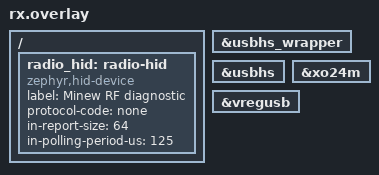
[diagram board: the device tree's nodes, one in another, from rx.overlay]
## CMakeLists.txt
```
cmake_minimum_required(VERSION 3.28.0)
find_package(Zephyr REQUIRED HINTS $ENV{ZEPHYR_BASE})
project(minew_radio_diagnostic)
if(NOT RADIO_ROLE MATCHES "^(tx|rx)$")
  message(FATAL_ERROR "RADIO_ROLE must be tx or rx")
endif()
target_compile_definitions(app PRIVATE RADIO_TX=$<STREQUAL:${RADIO_ROLE},tx>)
if(CONFIG_MINEW_RADIO_RELIABLE)
  target_sources(app PRIVATE src/reliable.c)
else()
  target_sources(app PRIVATE src/main.c)
endif()
if(CONFIG_MINEW_RADIO_CRYPTO_PROBE)
  target_sources(app PRIVATE src/crypto_probe.c)
endif()
if(CONFIG_MINEW_RADIO_DTLS_PROBE)
  target_sources(app PRIVATE src/dtls_probe.c)
endif()
if(CONFIG_MINEW_RADIO_SECURE)
  zephyr_include_directories(src)
  target_sources(app PRIVATE src/secure_dtls.c src/secure_pair.c)
endif()
if(RADIO_ROLE STREQUAL "rx")
  include(${ZEPHYR_BASE}/samples/subsys/usb/common/common.cmake)
  target_sources(app PRIVATE src/usb.c)
  if(CONFIG_MINEW_RADIO_KEYBOARD)
    target_sources(app PRIVATE src/keyboard_usb.c)
  endif()
endif()
```

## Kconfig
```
mainmenu "Minew 8 kHz radio diagnostic"
rsource "Kconfig.transport"
source "Kconfig.zephyr"
rsource "../upstream-zephyr/samples/subsys/usb/common/Kconfig.sample_usbd"
```

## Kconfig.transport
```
config MINEW_RADIO_RELIABLE
 bool "Experimental acknowledged radio transport"
 default n
 select ENTROPY_GENERATOR
 select REBOOT
 help
   Bounded diagnostic ARQ, sessions and channel reacquisition. Not encrypted.
config MINEW_RADIO_FREQUENCY_MHZ
 int "Fixed diagnostic radio frequency in MHz"
 range 2402 2480
 default 2408
 help
   Both transmitter and receiver must use the same frequency.
   This is a fixed-channel diagnostic, not adaptive channel hopping.
config MINEW_RADIO_CRYPTO_PROBE
 bool "Public-vector AEAD self-test and timing probe"
 depends on MINEW_RADIO_RELIABLE
 select PSA_CRYPTO
 select PSA_WANT_ALG_CCM
 select PSA_WANT_KEY_TYPE_AES
 select PSA_WANT_ALG_CHACHA20_POLY1305
 select PSA_WANT_KEY_TYPE_CHACHA20
 help
   Tests the pinned PSA provider before starting the existing unencrypted
   diagnostic. Uses a public test key, never a pairing secret. This option
   does not enable secure RF and must not be shipped as a secure transport.
config MINEW_RADIO_DTLS_PROBE
 bool "In-memory public-key DTLS conformance and timing probe"
 depends on MINEW_RADIO_CRYPTO_PROBE
 select MINEW_RADIO_DTLS
config MINEW_RADIO_DTLS
 bool
 select PSA_CRYPTO
 select PSA_WANT_ALG_CHACHA20_POLY1305
 select PSA_WANT_KEY_TYPE_CHACHA20
 select MBEDTLS_SSL_PROTO_TLS1_2
 select MBEDTLS_SSL_PROTO_DTLS
 select MBEDTLS_KEY_EXCHANGE_ECDHE_PSK_ENABLED
 select MBEDTLS_SSL_EXTENDED_MASTER_SECRET
 select PSA_WANT_ALG_TLS12_PRF
 select PSA_WANT_ALG_TLS12_PSK_TO_MS
 select PSA_WANT_ALG_SHA_256
 select PSA_WANT_ALG_ECDH
 select PSA_WANT_KEY_TYPE_DERIVE
 select PSA_WANT_KEY_TYPE_HMAC
 select PSA_WANT_KEY_TYPE_ECC_PUBLIC_KEY
 select PSA_WANT_KEY_TYPE_ECC_KEY_PAIR_IMPORT
 select PSA_WANT_KEY_TYPE_ECC_KEY_PAIR_EXPORT
 select PSA_WANT_KEY_TYPE_ECC_KEY_PAIR_GENERATE
 select PSA_WANT_ECC_SECP_R1_256
config MINEW_RADIO_SECURE
 bool "Experimental provisioned DTLS radio transport"
 depends on MINEW_RADIO_RELIABLE && !MINEW_RADIO_CRYPTO_PROBE
 select MINEW_RADIO_DTLS
 select FLASH
 select FLASH_MAP
 select FLASH_PAGE_LAYOUT
 select SETTINGS
 select ZMS
 help
   Requires a per-pair secret provisioned locally. No fixed test key or
   plaintext RF fallback. Uses the same ZMS format as the existing ZMK
   settings; never enable forced mount or replace it with NVS.
config MINEW_RADIO_KEYBOARD
 bool "Authenticated ZMK report transport"
 depends on MINEW_RADIO_SECURE
 help
   Separate ARQv5 address/format. Carries the pinned ZMK HKRO6 and full
   six-usage consumer reports. Diagnostic patterns cannot generate keys.
config MINEW_ZMK_RADIO_TX
 bool "Use real ZMK report producer"
 depends on MINEW_RADIO_KEYBOARD
```

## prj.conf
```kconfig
CONFIG_BT=n
CONFIG_NRFX_GPPI=y
CONFIG_SERIAL=n
CONFIG_CONSOLE=y
CONFIG_UART_CONSOLE=n
CONFIG_USE_SEGGER_RTT=y
CONFIG_RTT_CONSOLE=y
CONFIG_PRINTK=y
CONFIG_MAIN_STACK_SIZE=2048
CONFIG_ASSERT=y
```

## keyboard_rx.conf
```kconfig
CONFIG_SAMPLE_USBD_PRODUCT="Minew ZMK RF Receiver"
CONFIG_SAMPLE_USBD_PID=0x000a
```

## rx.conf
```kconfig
CONFIG_USB_DEVICE_STACK_NEXT=y
CONFIG_USBD_HID_IN_BUF_COUNT=4
CONFIG_SAMPLE_USBD_PRODUCT="Minew RF8K Diagnostic"
CONFIG_SAMPLE_USBD_MANUFACTURER="Experimental Minew port"
CONFIG_SAMPLE_USBD_PID=0x0009
```

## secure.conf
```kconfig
# No test PSK or plaintext fallback. Keep the existing ZMK ZMS format.
CONFIG_MBEDTLS_ENABLE_HEAP=y
CONFIG_MBEDTLS_HEAP_SIZE=49152
CONFIG_MAIN_STACK_SIZE=8192
CONFIG_SPEED_OPTIMIZATIONS=y
CONFIG_COMPILER_OPT="-O3"
CONFIG_MBEDTLS_SSL_IN_CONTENT_LEN=512
CONFIG_MBEDTLS_SSL_OUT_CONTENT_LEN=255
CONFIG_SETTINGS_ZMS=y
CONFIG_SETTINGS_ZMS_FORCE_MOUNT=n
CONFIG_ZMS_DATA_CRC=n
CONFIG_SETTINGS_ZMS_SECTOR_SIZE_MULT=1
CONFIG_SETTINGS_ZMS_CUSTOM_SECTOR_COUNT=n
```

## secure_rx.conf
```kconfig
# Required to handle a newly booted client using the same physical RF address.
CONFIG_MBEDTLS_USER_CONFIG_FILE="minew_secure_mbedtls.h"
```

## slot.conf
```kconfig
CONFIG_BOOTLOADER_MCUBOOT=y
CONFIG_ROM_START_OFFSET=0x800
CONFIG_MCUBOOT_BOOTUTIL_LIB=y
CONFIG_FLASH=y
CONFIG_FLASH_MAP=y
CONFIG_MCUBOOT_BOOTLOADER_MODE_SWAP_SCRATCH=y
CONFIG_IMG_MANAGER=y
CONFIG_STREAM_FLASH=y
CONFIG_RETAINED_MEM=y
CONFIG_REBOOT=y
```

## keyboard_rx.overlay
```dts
/ {
 keyboard_hid: keyboard-hid {
  compatible = "zephyr,hid-device";
  label = "Minew encrypted ZMK keyboard";
  protocol-code = "none";
  in-report-size = <64>;
  in-polling-period-us = <125>;
 };
};
```

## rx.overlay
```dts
&usbhs_wrapper { status = "okay"; };
zephyr_udc0: &usbhs { status = "okay"; };
&xo24m { status = "okay"; };
&vregusb { status = "okay"; };
/ {
 radio_hid: radio-hid {
  compatible = "zephyr,hid-device";
  label = "Minew RF diagnostic";
  protocol-code = "none";
  in-report-size = <64>;
  in-polling-period-us = <125>;
 };
};
```

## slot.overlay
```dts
#include "../bootloader/integration/layout.dtsi"
/ { chosen { zephyr,code-partition = &slot0_partition; }; };
&gpregret1 { status = "okay"; };
```

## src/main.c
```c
/* SPDX-License-Identifier: MIT */
#include <zephyr/kernel.h>
#include <zephyr/irq.h>
#include <zephyr/drivers/clock_control/nrf_clock_control.h>
#include <hal/nrf_radio.h>
#include <hal/nrf_timer.h>
#include <helpers/nrfx_gppi.h>
#include <string.h>
#include "frame.h"
#if IS_ENABLED(CONFIG_BOOTLOADER_MCUBOOT)
#include <zephyr/dfu/mcuboot.h>
#include <zephyr/drivers/retained_mem.h>
#include <zephyr/sys/reboot.h>
volatile uint32_t radio_recovery_request;
#endif

#define RADIO ((NRF_RADIO_Type *)DT_REG_ADDR(DT_NODELABEL(radio)))
#define TIMER ((NRF_TIMER_Type *)DT_REG_ADDR(DT_NODELABEL(timer21)))
/* S0/LENGTH absent: exactly 32 bytes on air, plus preamble/address/CRC. */
static uint8_t packet[FRAME_SIZE] __aligned(4);
volatile uint32_t radio_completed, radio_fresh, radio_missing, radio_duplicate;
volatile uint32_t radio_bad_crc, radio_bad_frame, radio_late, radio_heartbeat;
volatile uint32_t radio_last_sequence, radio_started;
volatile uint64_t radio_first_cycle, radio_last_cycle;

#if !RADIO_TX
static bool have_sequence;
#endif
#if RADIO_TX
static nrfx_gppi_handle_t pacing;
#endif
#if !RADIO_TX
int radio_usb_init(void);
void radio_usb_enqueue(const uint8_t *frame);
extern volatile uint32_t radio_usb_submitted, radio_usb_completed, radio_usb_dropped, radio_usb_errors;
#endif

static void radio_isr(const void *unused)
{
 ARG_UNUSED(unused);
 if (!nrf_radio_event_check(RADIO, NRF_RADIO_EVENT_END)) return;
 nrf_radio_event_clear(RADIO, NRF_RADIO_EVENT_END);
 radio_completed++;
 uint64_t now = k_cycle_get_64();
 if (radio_completed == 1) radio_first_cycle = now;
 radio_last_cycle = now;
#if RADIO_TX
 /* END leaves TXIDLE. Hardware START is periodic; skip mutation near the
  * next boundary rather than race EasyDMA. Repeat is counted by receiver. */
 unsigned int key = irq_lock();
 nrf_timer_task_trigger(TIMER, NRF_TIMER_TASK_CAPTURE1);
 uint32_t phase = nrf_timer_cc_get(TIMER, 1);
 if (phase < 2000 - 320 && nrf_radio_state_get(RADIO) == NRF_RADIO_STATE_TXIDLE) {
  frame_make(packet, ++radio_last_sequence);
 } else { radio_late++; }
 __DMB();
 irq_unlock(key);
#else
 if (!nrf_radio_crc_status_check(RADIO)) { radio_bad_crc++; return; }
 /* Snapshot promptly: continuous RX reuses EasyDMA storage for the next
  * frame. Validate and queue the snapshot, not a changing DMA buffer. */
 uint8_t received[FRAME_SIZE];
 memcpy(received, packet, sizeof(received));
 if (!frame_valid(received, sizeof(received))) { radio_bad_frame++; return; }
 uint32_t seq = frame_get32(received + 4);
 uint32_t delta = frame_forward_delta(radio_last_sequence, seq);
 if (!have_sequence || delta) {
  if (have_sequence) radio_missing += delta - 1;
  have_sequence = true; radio_last_sequence = seq; radio_fresh++;
  radio_usb_enqueue(received);
 } else { radio_duplicate++; }
#endif
}

int main(void)
{
#if !RADIO_TX
 int usb_err = radio_usb_init();
 if (usb_err) { printk("USB init error %d\n", usb_err); return usb_err; }
#endif
 int err = nrf_clock_control_request_sync(DEVICE_DT_GET(DT_NODELABEL(xo)), NULL, K_SECONDS(1));
 if (err) { printk("HFXO error %d\n", err); return err; }
 nrf_radio_mode_set(RADIO, NRF_RADIO_MODE_NRF_4MBIT_BT_0_6);
 nrf_radio_frequency_set(RADIO, CONFIG_MINEW_RADIO_FREQUENCY_MHZ);
 nrf_radio_txpower_set(RADIO, NRF_RADIO_TXPOWER_0DBM);
 nrf_radio_packet_conf_t cfg = {
  .lflen = 0, .s0len = 0, .s1len = 0,
  .plen = NRF_RADIO_PREAMBLE_LENGTH_16BIT,
  .maxlen = FRAME_SIZE, .statlen = FRAME_SIZE, .balen = 4,
  .big_endian = false, .whiteen = false,
 };
 nrf_radio_packet_configure(RADIO, &cfg);
 nrf_radio_base0_set(RADIO, 0x8e89bed6);
 nrf_radio_prefix0_set(RADIO, 0x73);
 nrf_radio_txaddress_set(RADIO, 0);
 nrf_radio_rxaddresses_set(RADIO, 1);
 nrf_radio_crc_configure(RADIO, 3, NRF_RADIO_CRC_ADDR_INCLUDE, 0x00065b);
 nrf_radio_crcinit_set(RADIO, 0x555555);
 nrf_radio_packetptr_set(RADIO, packet);
 IRQ_CONNECT(DT_IRQN(DT_NODELABEL(radio)), 2, radio_isr, NULL, 0);
 nrf_radio_event_clear(RADIO, NRF_RADIO_EVENT_END);
 nrf_radio_int_enable(RADIO, NRF_RADIO_INT_END_MASK);
 irq_enable(DT_IRQN(DT_NODELABEL(radio)));
#if RADIO_TX
 frame_make(packet, 0);
 nrf_timer_mode_set(TIMER, NRF_TIMER_MODE_TIMER);
 nrf_timer_bit_width_set(TIMER, NRF_TIMER_BIT_WIDTH_32);
 nrf_timer_prescaler_set(TIMER, NRF_TIMER_PRESCALER_CALCULATE(NRF_TIMER_BASE_FREQUENCY_GET(TIMER), 16000000));
 nrf_timer_cc_set(TIMER, 0, 2000); /* 125 us at 16 MHz */
 nrf_timer_shorts_enable(TIMER, NRF_TIMER_SHORT_COMPARE0_CLEAR_MASK);
 err = nrfx_gppi_conn_alloc(nrf_timer_event_address_get(TIMER, NRF_TIMER_EVENT_COMPARE0),
                           nrf_radio_task_address_get(RADIO, NRF_RADIO_TASK_START), &pacing);
 if (err) { printk("GPPI error %d\n", err); return err; }
 nrf_radio_task_trigger(RADIO, NRF_RADIO_TASK_TXEN);
 int64_t deadline = k_uptime_get() + 100;
 while (!nrf_radio_event_check(RADIO, NRF_RADIO_EVENT_READY)) {
  if (k_uptime_get() > deadline) { printk("RADIO ready timeout\n"); return -ETIMEDOUT; }
  k_busy_wait(1);
 }
 nrfx_gppi_conn_enable(pacing);
 nrf_timer_task_trigger(TIMER, NRF_TIMER_TASK_CLEAR);
 nrf_timer_task_trigger(TIMER, NRF_TIMER_TASK_START);
#else
 nrf_radio_shorts_set(RADIO, NRF_RADIO_SHORT_READY_START_MASK | NRF_RADIO_SHORT_END_START_MASK);
 nrf_radio_task_trigger(RADIO, NRF_RADIO_TASK_RXEN);
#endif
 radio_started = 1;
 printk("MINEW 4 Mbps %s diagnostic at %u MHz; 125 us target, no BLE/keys/authentication\n",
        RADIO_TX ? "TX" : "RX", CONFIG_MINEW_RADIO_FREQUENCY_MHZ);
 for (;;) {
  k_sleep(K_SECONDS(1)); radio_heartbeat++;
#if IS_ENABLED(CONFIG_BOOTLOADER_MCUBOOT)
  /* Bring-up health gate, deliberately independent of a second board. */
  if (radio_heartbeat == 5 && (!RADIO_TX || radio_completed)) {
   int confirm = boot_write_img_confirmed();
   printk("Diagnostic boot confirmation: %d\n", confirm);
  }
  if (radio_recovery_request == 3) {
   const struct device *retained = DEVICE_DT_GET(DT_NODELABEL(gpregret1));
   uint8_t request = 0xb1;
   if (device_is_ready(retained) && !retained_mem_write(retained, 0, &request, 1)) sys_reboot(SYS_REBOOT_COLD);
   radio_recovery_request = 0;
  }
#endif
  printk("end=%u fresh=%u missing=%u dup=%u crc=%u bad=%u late=%u\n",
   radio_completed, radio_fresh, radio_missing, radio_duplicate,
   radio_bad_crc, radio_bad_frame, radio_late);
#if !RADIO_TX
  printk("USB frames submitted=%u completed=%u dropped=%u errors=%u\n",
   radio_usb_submitted, radio_usb_completed, radio_usb_dropped, radio_usb_errors);
#endif
 }
}
```

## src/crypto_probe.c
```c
/* SPDX-License-Identifier: MIT */
/* PUBLIC TEST KEYS ONLY. This measures PSA; RF remains the unencrypted ARQv2. */
#include <zephyr/kernel.h>
#include <psa/crypto.h>
#include <string.h>
#include <errno.h>

/* magic, ABI, status(1 running/2 passed/3 failed), stage, PSA error, iterations,
 * then two groups of six: encrypt176 ns, decrypt176 ns, encrypt20 ns,
 * decrypt20 ns, tamper mask, known-answer passed (AES-CCM, then ChaChaPoly).
 * reserved[6]. Resolve from the exact flashed ELF. */
volatile uint32_t radio_crypto_probe_results[24];
static const uint8_t aad[] = "Minew secure RF v1";
static const uint8_t expected[] =
 "\x16\x35\xb6\x8b\x57\x0c\xfc\x85\x52\x9e\x39\xac\x91\x39\x10\xd7\xf3\x11\x16\x31\x62\x38\x67\xf1\x34\xe6\xe4\x41\x90\x4f\xd5\x04"
 "\xf5\x74\x6d\x6b\xf1\x89\x81\x5f\x51\xa4\x8f\x07\xc9\x94\xed\x9e\xee\x24\xe8\xd2\xea\xda\x7e\x42\x18\xb5\x88\xf6\x7a\x3a\xf1\xa3"
 "\x8d\xfe\xed\x70\xab\x5a\x15\x36\x28\x34\x0b\xa1\xf9\xf1\xee\x95\xc3\x2e\xa4\xf7\xa7\x98\x2f\x12\xee\xcc\x80\xb0\x3f\x0f\x2b\x66"
 "\x20\xcf\xa6\xc9\x47\x03\x89\xaf\xee\x56\xa5\x2b\x2f\x39\xc0\xc9\x48\xf5\x9c\x3d\xb0\x2e\x68\xdc\x18\x15\x52\x24\x0c\x47\x71\x42"
 "\x25\xf5\x67\x07\xfa\x4a\x96\xe2\x3e\x89\x70\xc9\x96\x1f\xdb\x4c\xe4\x73\x1e\xe7\xb0\xd2\x96\x98\xb7\x2d\xd1\x20\x15\x2d\x52\xfc"
 "\x18\x4d\x46\x02\x3c\x6d\x20\xfb\x6b\x6a\x44\xff\xf9\x78\xd7\x45\x52\xf8\x87\xb7\xee\xd5\x11\xcf\xdb\xaf\xfb\x8e\xcf\x72\xc3\xd5";
static const uint8_t chacha_expected[] =
 "\x89\xfa\x0a\x03\x2d\x12\xa3\x47\xbf\x8a\x35\xf8\x94\x10\x00\x6c\xd9\x61\xa0\xf4\x45\x61\xbb\xae\xfe\x8e\x35\xde\x69\xdd\xb8\x23"
 "\xcc\xa1\x0e\xd0\xc2\x3b\x97\xbf\x1f\x1b\x5c\xf3\x49\xb9\xa1\x0c\x4e\xb5\x9b\x47\xc9\x1d\x8e\xac\x2a\x81\xe3\x3c\xac\x72\xa0\xe9"
 "\x39\x39\xfe\x8e\xa1\x51\x6a\xae\x8c\x5f\x07\xf7\x54\x31\x92\xbe\x8a\x8f\x15\x61\x3b\x3f\xa6\x69\x56\x0e\xaa\x55\x84\x20\x5c\xe0"
 "\x2d\xbf\x0e\x90\x93\xbc\x41\x93\xd9\x32\x99\xdc\xce\xfc\xd9\xef\x99\x1e\x24\x4b\xfd\x28\x36\x8f\x37\x14\x4e\xa4\x05\x42\xc1\x39"
 "\x21\xe7\x41\x3e\x2d\xb6\x59\xeb\xc1\x9a\xf5\xf1\xa0\xb1\xe5\xb5\x24\xe0\x15\xe1\x9f\xfa\x5a\xc9\xaa\x78\x3d\xaa\x38\x86\x3e\xa6"
 "\x9f\x18\x23\x4b\x19\xe1\x32\x41\x26\xd7\xcc\xbb\xcb\x1c\x41\xaf\x19\x90\x1f\xc4\x06\x0b\xb4\xc7\xc2\xbc\x0a\xcf\x7b\x1c\x46\x38";
static psa_algorithm_t algorithm;
static size_t nonce_length;
static uint8_t key_bytes[32], nonce[13], plain[176], cipher[192], decoded[176];
static mbedtls_svc_key_id_t key;
#define CHECK(call) do { psa_status_t rc = (call); if (rc != PSA_SUCCESS) { radio_crypto_probe_results[4] = (uint32_t)rc; goto fail; } } while (0)

static psa_status_t seal(size_t n)
{
 size_t used;
 psa_status_t rc = psa_aead_encrypt(key, algorithm, nonce, nonce_length,
   aad, sizeof(aad)-1, plain, n, cipher, sizeof(cipher), &used);
 return rc ? rc : used == n + 16 ? PSA_SUCCESS : PSA_ERROR_CORRUPTION_DETECTED;
}
static psa_status_t open_packet(mbedtls_svc_key_id_t k, size_t n, const uint8_t *a)
{
 size_t used;
 psa_status_t rc = psa_aead_decrypt(k, algorithm, nonce, nonce_length,
   a, sizeof(aad)-1, cipher, n+16, decoded, sizeof(decoded), &used);
 return rc ? rc : used == n ? PSA_SUCCESS : PSA_ERROR_CORRUPTION_DETECTED;
}
static psa_status_t measure(bool encrypting, size_t n, unsigned result)
{
 nonce[0] = (uint8_t)n;
 CHECK(seal(n));
 uint64_t start = k_cycle_get_64();
 for (unsigned i = 0; i < 1000; i++) {
  if (encrypting) {
   for (unsigned j = 0; j < 8; j++) nonce[nonce_length-8+j] = ((uint64_t)i + 1) >> (8*j);
   CHECK(seal(n));
  } else CHECK(open_packet(key, n, aad));
 }
 radio_crypto_probe_results[result] = k_cyc_to_ns_floor64(k_cycle_get_64()-start) / 1000;
 return PSA_SUCCESS;
fail:
 return (psa_status_t)radio_crypto_probe_results[4];
}
static int probe_cipher(bool chacha, unsigned base)
{
 algorithm = chacha ? PSA_ALG_CHACHA20_POLY1305 : PSA_ALG_CCM;
 nonce_length = chacha ? 12 : 13;
 size_t key_length = chacha ? 32 : 16;
 mbedtls_svc_key_id_t wrong_key = 0;
 psa_key_attributes_t attributes = PSA_KEY_ATTRIBUTES_INIT;
 radio_crypto_probe_results[3] = chacha ? 7 : 1;
 for (unsigned i = 0; i < sizeof(key_bytes); i++) key_bytes[i] = i;
 for (unsigned i = 0; i < sizeof(nonce); i++) nonce[i] = i;
 for (unsigned i = 0; i < sizeof(plain); i++) plain[i] = i;
 CHECK(psa_crypto_init());
 radio_crypto_probe_results[3] = 2;
 psa_set_key_type(&attributes, chacha ? PSA_KEY_TYPE_CHACHA20 : PSA_KEY_TYPE_AES); psa_set_key_bits(&attributes, key_length * 8);
 psa_set_key_usage_flags(&attributes, PSA_KEY_USAGE_ENCRYPT | PSA_KEY_USAGE_DECRYPT);
 psa_set_key_algorithm(&attributes, algorithm);
 CHECK(psa_import_key(&attributes, key_bytes, key_length, &key));
 key_bytes[0] ^= 1;
 CHECK(psa_import_key(&attributes, key_bytes, key_length, &wrong_key));
 psa_reset_key_attributes(&attributes);
 radio_crypto_probe_results[3] = 3;
 CHECK(seal(sizeof(plain)));
 if (memcmp(chacha ? chacha_expected : expected, cipher, sizeof(cipher))) goto fail;
 CHECK(open_packet(key, sizeof(plain), aad));
 if (memcmp(plain, decoded, sizeof(plain))) goto fail;
 radio_crypto_probe_results[base+5] = 1;
 radio_crypto_probe_results[3] = 4;
 cipher[0] ^= 1;
 if (open_packet(key, sizeof(plain), aad) != PSA_ERROR_INVALID_SIGNATURE) goto fail;
 cipher[0] ^= 1; radio_crypto_probe_results[base+4] |= 1;
 cipher[sizeof(cipher)-1] ^= 1;
 if (open_packet(key, sizeof(plain), aad) != PSA_ERROR_INVALID_SIGNATURE) goto fail;
 cipher[sizeof(cipher)-1] ^= 1; radio_crypto_probe_results[base+4] |= 2;
 uint8_t wrong_aad[sizeof(aad)]; memcpy(wrong_aad, aad, sizeof(aad)); wrong_aad[0] ^= 1;
 if (open_packet(key, sizeof(plain), wrong_aad) != PSA_ERROR_INVALID_SIGNATURE) goto fail;
 radio_crypto_probe_results[base+4] |= 4; nonce[0] ^= 1;
 if (open_packet(key, sizeof(plain), aad) != PSA_ERROR_INVALID_SIGNATURE) goto fail;
 nonce[0] ^= 1; radio_crypto_probe_results[base+4] |= 8;
 if (open_packet(wrong_key, sizeof(plain), aad) != PSA_ERROR_INVALID_SIGNATURE) goto fail;
 radio_crypto_probe_results[base+4] |= 16;
 radio_crypto_probe_results[3] = 5; radio_crypto_probe_results[5] = 1000;
 CHECK(measure(true, 176, base)); CHECK(measure(false, 176, base+1));
 CHECK(measure(true, 20, base+2)); CHECK(measure(false, 20, base+3));
 CHECK(psa_destroy_key(wrong_key)); wrong_key = 0;
 CHECK(psa_destroy_key(key)); key = 0;
 return 0;
fail:
 if (wrong_key) psa_destroy_key(wrong_key);
 if (key) psa_destroy_key(key);
 psa_reset_key_attributes(&attributes);
 radio_crypto_probe_results[2] = 3;
 return -EIO;
}


int radio_crypto_probe(void)
{
 memset((void *)radio_crypto_probe_results, 0, sizeof(radio_crypto_probe_results));
 radio_crypto_probe_results[0] = 0x50433853; radio_crypto_probe_results[1] = 2;
 radio_crypto_probe_results[2] = 1;
 if (probe_cipher(false, 6) || probe_cipher(true, 12)) return -EIO;
 radio_crypto_probe_results[3] = 8; radio_crypto_probe_results[2] = 2;
 printk("PUBLIC-vector PSA AEAD probes passed; following RF is still UNENCRYPTED\n");
 return 0;
}
```

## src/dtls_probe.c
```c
/* SPDX-License-Identifier: MIT */
/* Two in-memory DTLS peers with PUBLIC TEST PSKs. No encrypted RF claim. */
#include <zephyr/kernel.h>
#include <mbedtls/ssl.h>
#include <mbedtls/ssl_cookie.h>
#include <mbedtls/ssl_ciphersuites.h>
#include <string.h>
#include <errno.h>

#define MTU 224
#define DEPTH 8
struct packet { size_t length; uint8_t bytes[MTU]; };
struct endpoint {
 mbedtls_ssl_context ssl;
 mbedtls_ssl_config conf;
 mbedtls_ssl_cookie_ctx cookie;
 struct endpoint *other;
 struct packet queue[DEPTH], last_application;
 unsigned head, count;
 int64_t timer_start;
 uint32_t intermediate, final;
};
static struct endpoint client, server;
static const int suites[] = {MBEDTLS_TLS_ECDHE_PSK_WITH_CHACHA20_POLY1305_SHA256, 0};
static const uint16_t groups[] = {MBEDTLS_SSL_IANA_TLS_GROUP_SECP256R1, 0};
static const uint8_t identity[] = "PUBLIC-Minew-DTLS-probe";
/* magic, ABI, status, stage, error, handshake ms, pair176 ns, pair20 ns,
 * suite, max datagram, cookie requests, wrong-key/replay/tamper/old-session/
 * reflection/truncation rejected, new-session ciphertext differs,
 * post-fault valid, iterations, sent, received, reserved[2]. */
volatile uint32_t radio_dtls_probe_results[24];

static int enqueue(struct endpoint *e, const uint8_t *p, size_t n)
{
 if (n > MTU) return MBEDTLS_ERR_SSL_BUFFER_TOO_SMALL;
 if (e->count == DEPTH) return MBEDTLS_ERR_SSL_WANT_WRITE;
 struct packet *q = &e->queue[(e->head + e->count++) % DEPTH];
 q->length = n; memcpy(q->bytes, p, n); return (int)n;
}
static int send_packet(void *context, const uint8_t *p, size_t n)
{
 struct endpoint *e = context;
 if (n > radio_dtls_probe_results[9]) radio_dtls_probe_results[9] = n;
 int rc = enqueue(e->other, p, n);
 if (rc >= 0) {
  radio_dtls_probe_results[20]++;
  if (n && p[0] == 23) { e->last_application.length = n; memcpy(e->last_application.bytes, p, n); }
 }
 return rc;
}
static int receive_packet(void *context, uint8_t *p, size_t n)
{
 struct endpoint *e = context;
 if (!e->count) return MBEDTLS_ERR_SSL_WANT_READ;
 struct packet *q = &e->queue[e->head];
 if (q->length > n) return MBEDTLS_ERR_SSL_BUFFER_TOO_SMALL;
 memcpy(p, q->bytes, q->length); int used = q->length;
 e->head = (e->head + 1) % DEPTH; e->count--;
 radio_dtls_probe_results[21]++; return used;
}
static void set_timer(void *context, uint32_t intermediate, uint32_t final)
{
 struct endpoint *e = context;
 e->timer_start = k_uptime_get(); e->intermediate = intermediate; e->final = final;
}
static int get_timer(void *context)
{
 struct endpoint *e = context;
 if (!e->final) return -1;
 int64_t elapsed = k_uptime_get() - e->timer_start;
 return elapsed >= e->final ? 2 : elapsed >= e->intermediate ? 1 : 0;
}
static void free_peers(void)
{
 struct endpoint *ends[] = {&client, &server};
 for (unsigned i = 0; i < 2; i++) {
  mbedtls_ssl_free(&ends[i]->ssl); mbedtls_ssl_config_free(&ends[i]->conf);
  mbedtls_ssl_cookie_free(&ends[i]->cookie);
 }
}
static int setup_peer(struct endpoint *e, bool is_server, bool wrong_key)
{
 uint8_t key[32]; for (unsigned i = 0; i < sizeof(key); i++) key[i] = i;
 if (wrong_key) key[0] ^= 1;
 int rc = mbedtls_ssl_config_defaults(&e->conf,
    is_server ? MBEDTLS_SSL_IS_SERVER : MBEDTLS_SSL_IS_CLIENT,
    MBEDTLS_SSL_TRANSPORT_DATAGRAM, MBEDTLS_SSL_PRESET_DEFAULT);
 if (rc) return rc;
 mbedtls_ssl_conf_ciphersuites(&e->conf, suites);
 mbedtls_ssl_conf_groups(&e->conf, groups);
 mbedtls_ssl_conf_min_tls_version(&e->conf, MBEDTLS_SSL_VERSION_TLS1_2);
 mbedtls_ssl_conf_max_tls_version(&e->conf, MBEDTLS_SSL_VERSION_TLS1_2);
 mbedtls_ssl_conf_handshake_timeout(&e->conf, 100, 1000);
 mbedtls_ssl_conf_dtls_anti_replay(&e->conf, MBEDTLS_SSL_ANTI_REPLAY_ENABLED);
 rc = mbedtls_ssl_conf_psk(&e->conf, key, sizeof(key), identity, sizeof(identity)-1);
 memset(key, 0, sizeof(key)); if (rc) return rc;
 if (is_server) {
  rc = mbedtls_ssl_cookie_setup(&e->cookie); if (rc) return rc;
  mbedtls_ssl_conf_dtls_cookies(&e->conf, mbedtls_ssl_cookie_write,
                               mbedtls_ssl_cookie_check, &e->cookie);
 }
 rc = mbedtls_ssl_setup(&e->ssl, &e->conf); if (rc) return rc;
 mbedtls_ssl_set_bio(&e->ssl, e, send_packet, receive_packet, NULL);
 mbedtls_ssl_set_timer_cb(&e->ssl, e, set_timer, get_timer);
 mbedtls_ssl_set_mtu(&e->ssl, MTU);
 if (is_server) return mbedtls_ssl_set_client_transport_id(&e->ssl, identity, sizeof(identity)-1);
 return 0;
}
static int start_peers(bool wrong_key)
{
 memset(&client, 0, sizeof(client)); memset(&server, 0, sizeof(server));
 struct endpoint *ends[] = {&client, &server};
 for (unsigned i = 0; i < 2; i++) {
  mbedtls_ssl_init(&ends[i]->ssl); mbedtls_ssl_config_init(&ends[i]->conf);
  mbedtls_ssl_cookie_init(&ends[i]->cookie);
 }
 client.other = &server; server.other = &client;
 int rc = setup_peer(&client, false, false); if (rc) return rc;
 return setup_peer(&server, true, wrong_key);
}
static int handshake(void)
{
 int64_t end = k_uptime_get() + 5000;
 while (k_uptime_get() < end) {
  struct endpoint *ends[] = {&client, &server};
  for (unsigned i = 0; i < 2; i++) {
   struct endpoint *e = ends[i];
   if (mbedtls_ssl_is_handshake_over(&e->ssl)) continue;
   int rc = mbedtls_ssl_handshake(&e->ssl);
   if (rc == MBEDTLS_ERR_SSL_HELLO_VERIFY_REQUIRED && i == 1) {
    radio_dtls_probe_results[10]++;
    rc = mbedtls_ssl_session_reset(&e->ssl); if (rc) return rc;
    mbedtls_ssl_set_mtu(&e->ssl, MTU);
    rc = mbedtls_ssl_set_client_transport_id(&e->ssl, identity, sizeof(identity)-1);
   }
   if (rc && rc != MBEDTLS_ERR_SSL_WANT_READ && rc != MBEDTLS_ERR_SSL_WANT_WRITE) return rc;
  }
  if (mbedtls_ssl_is_handshake_over(&client.ssl) && mbedtls_ssl_is_handshake_over(&server.ssl)) return 0;
  k_sleep(K_MSEC(1));
 }
 return MBEDTLS_ERR_SSL_TIMEOUT;
}
static int roundtrip(size_t length)
{
 uint8_t plain[176], out[176]; for (unsigned i = 0; i < sizeof(plain); i++) plain[i] = i;
 int rc = mbedtls_ssl_write(&client.ssl, plain, length);
 if (rc != (int)length) return rc < 0 ? rc : -EIO;
 rc = mbedtls_ssl_read(&server.ssl, out, sizeof(out));
 return rc == (int)length && !memcmp(plain, out, length) ? 0 : rc < 0 ? rc : -EIO;
}
static int reject(struct endpoint *e, const struct packet *p)
{
 uint8_t out[176];
 int rc = enqueue(e, p->bytes, p->length); if (rc < 0) return rc;
 rc = mbedtls_ssl_read(&e->ssl, out, sizeof(out));
 return rc == MBEDTLS_ERR_SSL_WANT_READ ? 0 : rc < 0 ? rc : -EIO;
}
int radio_dtls_probe(void)
{
 int rc = 0;
#define TRY(call) do { rc = (call); if (rc) goto done; } while (0)
 memset((void *)radio_dtls_probe_results, 0, sizeof(radio_dtls_probe_results));
 radio_dtls_probe_results[0] = 0x50433844; radio_dtls_probe_results[1] = 1;
 radio_dtls_probe_results[2] = 1; radio_dtls_probe_results[3] = 1;
 TRY(start_peers(false));
 int64_t start = k_uptime_get(); TRY(handshake());
 radio_dtls_probe_results[5] = k_uptime_get() - start;
 radio_dtls_probe_results[8] = MBEDTLS_TLS_ECDHE_PSK_WITH_CHACHA20_POLY1305_SHA256;
 radio_dtls_probe_results[3] = 2;
 TRY(roundtrip(176)); struct packet old = client.last_application;
 TRY(reject(&server, &old)); radio_dtls_probe_results[12] = 1;
 struct packet tampered = old; tampered.bytes[tampered.length-1] ^= 1;
 /* A new, not-yet-seen sequence reaches AEAD verification rather than only
  * the replay filter. Corrupt the next record before the receiver reads it. */
 uint8_t input[176] = {0};
 rc = mbedtls_ssl_write(&client.ssl, input, sizeof(input));
 if (rc != 176) { if (rc >= 0) rc = -EIO; goto done; }
 tampered = client.last_application; tampered.bytes[tampered.length-1] ^= 1;
 server.count = 0;
 TRY(reject(&server, &tampered)); radio_dtls_probe_results[13] = 1;
 TRY(reject(&client, &client.last_application)); radio_dtls_probe_results[15] = 1;
 tampered.length = 7; TRY(reject(&server, &tampered)); radio_dtls_probe_results[16] = 1;
 TRY(roundtrip(176)); radio_dtls_probe_results[18] = 1;
 radio_dtls_probe_results[3] = 3; radio_dtls_probe_results[19] = 1000;
 for (unsigned j = 0; j < 2; j++) {
  uint64_t cycles = k_cycle_get_64();
  for (unsigned i = 0; i < 1000; i++) TRY(roundtrip(j ? 20 : 176));
  radio_dtls_probe_results[6+j] = k_cyc_to_ns_floor64(k_cycle_get_64()-cycles)/1000;
 }
 free_peers(); TRY(start_peers(false)); TRY(handshake());
 radio_dtls_probe_results[3] = 4;
 TRY(reject(&server, &old)); radio_dtls_probe_results[14] = 1;
 TRY(roundtrip(176));
 if (old.length != client.last_application.length ||
     memcmp(old.bytes, client.last_application.bytes, old.length)) radio_dtls_probe_results[17] = 1;
 else { rc = -EIO; goto done; }
 free_peers(); TRY(start_peers(true));
 radio_dtls_probe_results[3] = 5;
 rc = handshake();
 radio_dtls_probe_results[22] = (uint32_t)rc;
 if (rc == 0 || mbedtls_ssl_is_handshake_over(&client.ssl) || mbedtls_ssl_is_handshake_over(&server.ssl)) {
  rc = -EIO; goto done;
 }
 radio_dtls_probe_results[11] = 1; rc = 0;
 radio_dtls_probe_results[3] = 6;
done:
 radio_dtls_probe_results[4] = (uint32_t)rc;
 radio_dtls_probe_results[2] = rc ? 3 : 2;
 free_peers();
 return rc ? -EIO : 0;
}
```

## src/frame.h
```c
/* SPDX-License-Identifier: MIT */
#ifndef MINEW_RADIO_FRAME_H
#define MINEW_RADIO_FRAME_H
#include <stdint.h>
#include <stdbool.h>
#include <stddef.h>
#if defined(CONFIG_MINEW_RADIO_KEYBOARD)
#include "keyboard_frame.h"
#endif
/* Diagnostic only: fixed 32-byte payload, explicitly little endian. */
#define FRAME_SIZE 32
/* 0: duplicate/backward; positive: forward distance (wrap-aware). */
static inline uint32_t frame_forward_delta(uint32_t previous, uint32_t current)
{
 uint32_t delta = current - previous;
 return delta < UINT32_C(0x80000000) ? delta : 0;
}
static inline void frame_put32(uint8_t *p, uint32_t v)
{ for (unsigned i = 0; i < 4; i++) p[i] = v >> (8 * i); }
static inline uint32_t frame_get32(const uint8_t *p)
{ return (uint32_t)p[0] | (uint32_t)p[1] << 8 | (uint32_t)p[2] << 16 | (uint32_t)p[3] << 24; }
static inline void frame_make(uint8_t *p, uint32_t seq)
{
 p[0] = 'M'; p[1] = '8'; p[2] = 1; p[3] = 0;
 frame_put32(p + 4, seq);
 for (unsigned i = 8; i < FRAME_SIZE; i++) p[i] = (uint8_t)(seq + i * 17);
}
static inline bool frame_valid(const uint8_t *p, size_t len)
{
 #if defined(CONFIG_MINEW_RADIO_KEYBOARD)
 if (len == FRAME_SIZE && p[0] == 'M' && p[1] == '8' && p[2] == 3 && !p[3])
  return frame_get32(p+28) && rf_keyboard_payload_valid(p+8);
#endif
 if (len != FRAME_SIZE || p[0] != 'M' || p[1] != '8' || (p[2] != 1 && p[2] != 2) || p[3]) return false;
 uint32_t seq = frame_get32(p + 4);
 unsigned end = p[2] == 2 ? 28 : FRAME_SIZE;
 if (p[2] == 2 && !frame_get32(p + 28)) return false;
 for (unsigned i = 8; i < end; i++) if (p[i] != (uint8_t)(seq + i * 17)) return false;
 return true;
}
static inline void frame_make_session(uint8_t *p, uint32_t seq, uint32_t epoch)
{
 frame_make(p, seq); p[2] = 2; frame_put32(p + 28, epoch);
}
#endif
```

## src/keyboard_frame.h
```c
/* SPDX-License-Identifier: MIT */
#ifndef MINEW_KEYBOARD_FRAME_H
#define MINEW_KEYBOARD_FRAME_H
#include <stdint.h>
#include <stdbool.h>
#include <stddef.h>
#include <string.h>
/* Exact pinned ZMK baseline: ID 1 = modifiers/reserved/six keys;
 * ID 2 = six little-endian 12-bit consumer usages. */
#define RF_KEYBOARD_REPORT_SIZE 9
#define RF_CONSUMER_REPORT_SIZE 13
#define RF_REPORT_MAX 18
#define RF_REPORT_PAYLOAD 20
static inline bool rf_keyboard_payload_valid(const uint8_t *p)
{
 unsigned n = p[0];
 if (p[1] || n > RF_REPORT_MAX) return false;
 if (p[2] == 1) {
  if (n != RF_KEYBOARD_REPORT_SIZE || p[4]) return false;
 } else if (p[2] == 2) {
  if (n != RF_CONSUMER_REPORT_SIZE) return false;
  for (unsigned i = 4; i < 2+n; i += 2) if (p[i] & 0xf0) return false;
 } else return false;
 for (unsigned i = 2+n; i < RF_REPORT_PAYLOAD; i++) if (p[i]) return false;
 return true;
}
static inline bool rf_keyboard_payload_make(uint8_t *p, const uint8_t *report, size_t n)
{
 if (n > RF_REPORT_MAX) return false;
 memset(p, 0, RF_REPORT_PAYLOAD); p[0] = n; memcpy(p+2, report, n);
 return rf_keyboard_payload_valid(p);
}
#endif
```

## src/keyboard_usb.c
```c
/* Copyright (c) 2020 The ZMK Contributors
 * SPDX-License-Identifier: MIT
 * Descriptor layout adapted from the pinned ZMK HID report definitions. */
#include <zephyr/kernel.h>
#include <zephyr/sys/atomic.h>
#include <zephyr/usb/usbd.h>
#include <zephyr/usb/class/usbd_hid.h>
#include <string.h>
#include "frame.h"
#include "reliable.h"
#include "keyboard_frame.h"
/* Match the pinned ZMK HKRO=6, consumer FULL=6 reports exactly. */
static const uint8_t descriptor[] = {
 0x05,0x01,0x09,0x06,0xa1,0x01,0x85,0x01,
 0x05,0x07,0x19,0xe0,0x29,0xe7,0x15,0x00,0x25,0x01,0x75,0x01,0x95,0x08,0x81,0x02,
 0x75,0x08,0x95,0x01,0x81,0x03,
 0x15,0x00,0x26,0xff,0x00,0x19,0x00,0x29,0xff,0x75,0x08,0x95,0x06,0x81,0x00,0xc0,
 0x05,0x0c,0x09,0x01,0xa1,0x01,0x85,0x02,
 0x15,0x00,0x26,0xff,0x0f,0x19,0x00,0x2a,0xff,0x0f,0x75,0x10,0x95,0x06,0x81,0x00,0xc0
};
static const struct device *const keyboard = DEVICE_DT_GET(DT_NODELABEL(keyboard_hid));
extern volatile uint32_t radio_security_stats[10], radio_link_stats[LS_COUNT];
static atomic_t ready, used;
K_SEM_DEFINE(keyboard_available, 4, 4);
UDC_STATIC_BUF_DEFINE(buffers, 4*64);
struct key_event { uint32_t epoch; uint8_t payload[RF_REPORT_PAYLOAD]; };
K_MSGQ_DEFINE(events, sizeof(struct key_event), 64, 4);
static uint8_t cached[2][RF_REPORT_PAYLOAD], current[2][RF_REPORT_MAX];
static uint32_t producer_epoch;
static int64_t last_fresh;
static atomic_t overflow;
volatile uint32_t radio_keyboard_submitted, radio_keyboard_completed, radio_keyboard_errors;
volatile uint32_t radio_keyboard_queue_errors, radio_keyboard_failsafe_releases;
static bool authenticated(uint32_t epoch)
{ return radio_security_stats[0] == 2 && radio_link_stats[LS_STATE] &&
         epoch && epoch == radio_link_stats[LS_REMOTE_EPOCH]; }
void radio_keyboard_offer_frame(const uint8_t *frame)
{
 if (!frame_valid(frame, FRAME_SIZE) || frame[2] != 3 || !authenticated(frame_get32(frame+28))) return;
 unsigned key = irq_lock();
 uint32_t epoch = frame_get32(frame+28);
 if (producer_epoch != epoch) { producer_epoch = epoch; memset(cached, 0, sizeof(cached)); k_msgq_purge(&events); }
 last_fresh = k_uptime_get();
 unsigned index = frame[10]-1;
 if (memcmp(cached[index], frame+8, RF_REPORT_PAYLOAD)) {
  struct key_event e = {.epoch = epoch}; memcpy(e.payload, frame+8, RF_REPORT_PAYLOAD);
  if (k_msgq_put(&events, &e, K_NO_WAIT)) { radio_keyboard_queue_errors++; atomic_set(&overflow, 1); }
  else memcpy(cached[index], e.payload, RF_REPORT_PAYLOAD);
 }
 irq_unlock(key);
}
static void iface_ready(const struct device *dev, bool value)
{ ARG_UNUSED(dev); atomic_set(&ready, value); atomic_set(&overflow, 1); }
static void done(const struct device *dev, const uint8_t *report)
{
 ARG_UNUSED(dev); ptrdiff_t offset = report-buffers;
 if (offset >= 0 && offset < sizeof(buffers) && !(offset%64)) {
  radio_keyboard_completed++; atomic_clear_bit(&used, offset/64); k_sem_give(&keyboard_available);
 }
}
static int size(const struct device *dev, uint8_t type, uint8_t id)
{
 ARG_UNUSED(dev); if (type != HID_REPORT_TYPE_INPUT) return -ENOTSUP;
 return id == 1 ? RF_KEYBOARD_REPORT_SIZE : id == 2 ? RF_CONSUMER_REPORT_SIZE : -ENOTSUP;
}
static int get(const struct device *dev, uint8_t type, uint8_t id, uint16_t len, uint8_t *buf)
{
 int n = size(dev,type,id); if (n < 0) return n;
 unsigned key = irq_lock(); n = MIN(n,len); memcpy(buf,current[id-1],n); irq_unlock(key); return n;
}
static const struct hid_device_ops ops = {
 .iface_ready = iface_ready, .input_report_done = done, .get_report_size = size, .get_report = get,
};
int radio_keyboard_init(void)
{
 current[0][0] = 1; current[1][0] = 2;
 return device_is_ready(keyboard) ? hid_device_register(keyboard,descriptor,sizeof(descriptor),&ops) : -ENODEV;
}
static bool send(const uint8_t *p, size_t n)
{
 if (!atomic_get(&ready) || k_sem_take(&keyboard_available,K_MSEC(20))) return false;
 for (unsigned i=0;i<4;i++) if (!atomic_test_and_set_bit(&used,i)) {
  memcpy(buffers+i*64,p,n);
  int err = hid_device_submit_report(keyboard,n,buffers+i*64);
  if (err) { atomic_clear_bit(&used,i); k_sem_give(&keyboard_available); radio_keyboard_errors++; return false; }
  unsigned key=irq_lock(); memcpy(current[p[0]-1],p,n); irq_unlock(key);
  radio_keyboard_submitted++; return true;
 }
 k_sem_give(&keyboard_available); radio_keyboard_errors++; return false;
}
static bool neutral(void)
{
 uint8_t key[RF_KEYBOARD_REPORT_SIZE]={1}, consumer[RF_CONSUMER_REPORT_SIZE]={2};
 bool a=send(key,sizeof(key)), b=send(consumer,sizeof(consumer));
 return a && b;
}
static void worker(void *a, void *b, void *c)
{
 ARG_UNUSED(a); ARG_UNUSED(b); ARG_UNUSED(c);
 uint32_t active_epoch=0; bool released=false;
 for (;;) {
  struct key_event e;
  int rc=k_msgq_get(&events,&e,K_MSEC(10));
  unsigned key=irq_lock(); int64_t last=last_fresh; irq_unlock(key);
  bool live=authenticated(radio_link_stats[LS_REMOTE_EPOCH]) && k_uptime_get()-last<300;
  if (atomic_get(&overflow) || !live) {
   if (!released || atomic_get(&overflow)) {
    if (!neutral()) { k_sleep(K_MSEC(1)); continue; }
    radio_keyboard_failsafe_releases++; released=true; active_epoch=0;
    key=irq_lock(); k_msgq_purge(&events); memset(cached,0,sizeof(cached)); atomic_clear(&overflow); irq_unlock(key);
   }
   continue;
  }
  if (rc || !authenticated(e.epoch)) continue;
  if (active_epoch != e.epoch) {
   if (!neutral()) { atomic_set(&overflow,1); continue; }
   active_epoch=e.epoch;
  }
  released=false;
  if (!send(e.payload+2,e.payload[0])) atomic_set(&overflow,1);
 }
}
K_THREAD_DEFINE(keyboard_forward_thread,2048,worker,NULL,NULL,NULL,4,0,0);
void radio_keyboard_snapshot(uint32_t out[7])
{
 out[0]=radio_keyboard_submitted; out[1]=radio_keyboard_completed; out[2]=radio_keyboard_errors;
 out[3]=radio_keyboard_queue_errors; out[4]=radio_keyboard_failsafe_releases; out[5]=atomic_get(&ready);
 out[6]=0;
 for (unsigned i=1;i<RF_KEYBOARD_REPORT_SIZE;i++) if (current[0][i]) out[6]|=1;
 for (unsigned i=1;i<RF_CONSUMER_REPORT_SIZE;i++) if (current[1][i]) out[6]|=2;
}

bool radio_keyboard_is_ready(void) { return atomic_get(&ready); }
```

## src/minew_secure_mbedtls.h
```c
/* SPDX-License-Identifier: MIT */
#ifndef MINEW_SECURE_MBEDTLS_H
#define MINEW_SECURE_MBEDTLS_H
/* Cookie validation only starts a new handshake. Application state must remain
 * unauthenticated until that handshake verifies the configured pair identity. */
#define MBEDTLS_SSL_DTLS_CLIENT_PORT_REUSE
#endif
```

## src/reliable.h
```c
/* SPDX-License-Identifier: MIT */
#ifndef MINEW_RELIABLE_H
#define MINEW_RELIABLE_H
#include "frame.h"
#include <string.h>
#ifndef ARQ_BATCH
#if defined(CONFIG_MINEW_RADIO_SECURE)
#define ARQ_BATCH 10
#else
#define ARQ_BATCH 8
#endif
#endif
#ifndef ARQ_WIRE_VERSION
#if defined(CONFIG_MINEW_RADIO_SECURE)
#if defined(CONFIG_MINEW_RADIO_KEYBOARD)
#define ARQ_WIRE_VERSION 5
#else
#define ARQ_WIRE_VERSION 4
#endif
#else
#define ARQ_WIRE_VERSION 2
#endif
#endif
#if ARQ_WIRE_VERSION >= 4
#define ARQ_WINDOW 4
#else
#define ARQ_WINDOW 1
#endif
#define ARQ_HEADER 16
#define ARQ_SAMPLE_BYTES 20
#define ARQ_MAX_PAYLOAD (ARQ_HEADER + ARQ_BATCH * ARQ_SAMPLE_BYTES)
#define ARQ_TX_DWELL_MS 90
enum {
 LS_LOCAL_EPOCH, LS_REMOTE_EPOCH, LS_STATE, LS_ACK_SENT, LS_DATA_PACKETS,
 LS_RETRIES, LS_BUSY, LS_CHANNEL, LS_HOPS, LS_INJECT_DATA, LS_INJECT_ACK,
 LS_RESTARTS, LS_BACKPRESSURE, LS_TIMEOUTS, LS_DISCARDED, LS_QUEUE_OVERFLOW,
 LS_SAMPLES, LS_MAX_QUEUE, LS_MAX_ACK_US, LS_DATA_SENT, LS_ACK_RECEIVED,
 LS_LINK_LOSS, LS_SAMPLE_LATE, LS_RESERVED, LS_COUNT
};
enum { ARQ_DATA = 1, ARQ_ACK = 2, ARQ_HELLO = 3, ARQ_POLL = 4 };
#define ARQ_ACK_REQUEST 1
enum { ARQ_COMMITTED = 0, ARQ_BUSY = 1, ARQ_RESET = 2, ARQ_READY = 3 };
enum { ARQ_EXPECTED, ARQ_DUPLICATE, ARQ_WRONG_SEQUENCE };
static inline void arq_header(uint8_t *p, uint8_t type, uint32_t epoch,
                              uint32_t seq, uint8_t count, uint8_t status)
{
 memset(p, 0, ARQ_HEADER); p[0] = 'R'; p[1] = '8'; p[2] = ARQ_WIRE_VERSION; p[3] = type;
 frame_put32(p + 4, epoch); frame_put32(p + 8, seq); p[12] = count; p[13] = status;
}
static inline bool arq_valid(const uint8_t *p, size_t len)
{
 if (len < ARQ_HEADER || len > ARQ_MAX_PAYLOAD || p[0] != 'R' || p[1] != '8' ||
     p[2] != ARQ_WIRE_VERSION || !frame_get32(p + 4) || p[14] || p[15]) return false;
 if (p[3] == ARQ_HELLO) return len == ARQ_HEADER && !p[12] && !p[13] && !frame_get32(p + 8);
 if (ARQ_WIRE_VERSION >= 4 && p[3] == ARQ_POLL) return len == ARQ_HEADER && !p[12] && !p[13];
 if (p[3] == ARQ_ACK) return len == 20 && (ARQ_WIRE_VERSION >= 4 ? !p[12] : p[12] <= ARQ_BATCH) && p[13] <= ARQ_READY && frame_get32(p + 16);
 if (p[3] != ARQ_DATA || !p[12] || p[12] > ARQ_BATCH || (ARQ_WIRE_VERSION >= 4 && p[12] != ARQ_BATCH) || (p[13] & ~(ARQ_WIRE_VERSION >= 4 ? ARQ_ACK_REQUEST : 0)) ||
     len != ARQ_HEADER + (size_t)p[12] * ARQ_SAMPLE_BYTES) return false;
 for (unsigned i = 0; i < p[12]; i++) {
  const uint8_t *sample = p + ARQ_HEADER + i * ARQ_SAMPLE_BYTES;
  uint32_t seq = frame_get32(p + 8) + i;
#if defined(CONFIG_MINEW_RADIO_KEYBOARD)
  (void)seq;
  if (!rf_keyboard_payload_valid(sample)) return false;
#else
  for (unsigned j = 0; j < ARQ_SAMPLE_BYTES; j++) {
   if (sample[j] != (uint8_t)(seq + (j + 8) * 17)) return false;
  }
#endif
 }
 return true;
}
/* Shared constant metadata is encoded once. All 20 sample data bytes remain
 * opaque on transmission and are copied back, never regenerated from sequence. */
static inline size_t arq_pack_data(uint8_t *p, const uint8_t *frames, uint8_t count)
{
 if (!count || count > ARQ_BATCH || (ARQ_WIRE_VERSION >= 4 && count != ARQ_BATCH)) return 0;
 uint32_t epoch = frame_get32(frames + 28), seq = frame_get32(frames + 4);
 for (unsigned i = 0; i < count; i++) {
  const uint8_t *f = frames + i * FRAME_SIZE;
  if (!frame_valid(f, FRAME_SIZE) || f[2] != (ARQ_WIRE_VERSION == 5 ? 3 : 2) || frame_get32(f + 4) != seq + i ||
      frame_get32(f + 28) != epoch) return 0;
 }
 arq_header(p, ARQ_DATA, epoch, seq, count, 0);
 for (unsigned i = 0; i < count; i++) memcpy(p + ARQ_HEADER + i * ARQ_SAMPLE_BYTES,
                                           frames + i * FRAME_SIZE + 8, ARQ_SAMPLE_BYTES);
 return ARQ_HEADER + (size_t)count * ARQ_SAMPLE_BYTES;
}
static inline bool arq_unpack_data(const uint8_t *p, size_t len, uint8_t *frames)
{
 if (!arq_valid(p, len) || p[3] != ARQ_DATA) return false;
 for (unsigned i = 0; i < p[12]; i++) {
  uint8_t *f = frames + i * FRAME_SIZE;
  f[0] = 'M'; f[1] = '8'; f[2] = ARQ_WIRE_VERSION == 5 ? 3 : 2; f[3] = 0;
  frame_put32(f + 4, frame_get32(p + 8) + i);
  memcpy(f + 8, p + ARQ_HEADER + i * ARQ_SAMPLE_BYTES, ARQ_SAMPLE_BYTES);
  frame_put32(f + 28, frame_get32(p + 4));
 }
 return true;
}
struct arq_receiver {
 uint32_t epoch, expected, last_base, retired[4];
 uint8_t last_count, retired_index, history_count;
};
struct arq_receive_window { uint32_t start, limit; bool packet_started; };
/* An idle-listen deadline must not truncate a frame whose address matched
 * before the deadline. Extend once, with a separate bounded packet budget. */
static inline bool arq_receive_expired(struct arq_receive_window *w, uint32_t now,
                                       bool address, uint32_t packet_limit)
{
 if (address && !w->packet_started) {
  w->packet_started = true; w->start = now; w->limit = packet_limit;
 }
 return (uint32_t)(now - w->start) >= w->limit;
}
/* HELLO establishes a new diagnostic epoch; old epochs cannot switch it back. */
static inline bool arq_begin(struct arq_receiver *r, uint32_t epoch)
{
 if (!epoch) return false;
 if (epoch == r->epoch) return true;
 for (unsigned i = 0; i < 4; i++) if (r->retired[i] == epoch) return false;
 if (r->epoch) r->retired[r->retired_index++ % 4] = r->epoch;
 r->epoch = epoch; r->expected = 0; r->last_count = r->history_count = 0;
 return true;
}
static inline int arq_classify(const struct arq_receiver *r, uint32_t base, uint8_t count)
{
 if (base == r->expected) return ARQ_EXPECTED;
 if (ARQ_WIRE_VERSION >= 4 && count == ARQ_BATCH && r->last_count) {
  uint32_t behind = r->expected - base;
  if (behind && behind <= (uint32_t)r->history_count * ARQ_BATCH && !(behind % ARQ_BATCH)) return ARQ_DUPLICATE;
 }
 if (r->last_count == count && r->last_count && r->last_base == base) return ARQ_DUPLICATE;
 return ARQ_WRONG_SEQUENCE;
}
/* Call only after all samples have been accepted into the USB delivery queue. */
static inline void arq_commit(struct arq_receiver *r, uint32_t base, uint8_t count)
{
 r->last_base = base; r->last_count = count; r->expected = base + count;
 if (r->history_count < ARQ_WINDOW) r->history_count++;
}
static inline int arq_window_progress(uint32_t first, uint32_t acknowledged)
{
 uint32_t advance = acknowledged-first;
 return advance <= ARQ_WINDOW * ARQ_BATCH && !(advance % ARQ_BATCH) ? (int)(advance/ARQ_BATCH) : -1;
}
#endif
```

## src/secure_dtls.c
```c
/* SPDX-License-Identifier: MIT */
#include <zephyr/kernel.h>
#include <mbedtls/ssl_ciphersuites.h>
#include <mbedtls/platform_util.h>
#include "secure_dtls.h"
#include <string.h>
#if defined(CONFIG_MINEW_RADIO_SECURE) && !RADIO_TX
#ifndef MBEDTLS_SSL_DTLS_CLIENT_PORT_REUSE
#error "Secure receiver requires cookie-checked DTLS client reconnect support"
#endif
#endif

static const int suites[] = {MBEDTLS_TLS_ECDHE_PSK_WITH_CHACHA20_POLY1305_SHA256, 0};
static const uint16_t groups[] = {MBEDTLS_SSL_IANA_TLS_GROUP_SECP256R1, 0};
/* The pinned PSA provider is not configured with its own threading layer.
 * Serialize all TLS/PSA allocation and credential-preservation hashing. */
K_MUTEX_DEFINE(radio_crypto_mutex);
static void set_timer(void *ctx, uint32_t intermediate, uint32_t final)
{
 struct rf_dtls *s = ctx;
 s->timer_start = k_uptime_get(); s->intermediate = intermediate; s->final = final;
}
static int get_timer(void *ctx)
{
 struct rf_dtls *s = ctx;
 if (!s->final) return -1;
 int64_t elapsed = k_uptime_get() - s->timer_start;
 return elapsed >= s->final ? 2 : elapsed >= s->intermediate ? 1 : 0;
}
void rf_dtls_free(struct rf_dtls *s)
{
 if (!s->initialized) return;
 k_mutex_lock(&radio_crypto_mutex, K_FOREVER);
 mbedtls_ssl_free(&s->ssl); mbedtls_ssl_config_free(&s->conf);
 mbedtls_ssl_cookie_free(&s->cookie);
 mbedtls_platform_zeroize(s, sizeof(*s));
 k_mutex_unlock(&radio_crypto_mutex);
}
static int initialize(struct rf_dtls *s, bool server, const uint8_t id[16], const uint8_t key[32],
                 void *io, mbedtls_ssl_send_t *send, mbedtls_ssl_recv_t *receive)
{
 int rc;
 if (s->initialized) return MBEDTLS_ERR_SSL_BAD_INPUT_DATA;
 memset(s, 0, sizeof(*s)); s->initialized = true; s->server = server;
 mbedtls_ssl_init(&s->ssl); mbedtls_ssl_config_init(&s->conf);
 mbedtls_ssl_cookie_init(&s->cookie);
 memcpy(s->identity, "Minew-RF-v1:", 12); memcpy(s->identity + 12, id, 16);
#define TRY(call) do { rc = (call); if (rc) goto fail; } while (0)
 TRY(mbedtls_ssl_config_defaults(&s->conf, server ? MBEDTLS_SSL_IS_SERVER : MBEDTLS_SSL_IS_CLIENT,
                                 MBEDTLS_SSL_TRANSPORT_DATAGRAM, MBEDTLS_SSL_PRESET_DEFAULT));
 mbedtls_ssl_conf_ciphersuites(&s->conf, suites);
 mbedtls_ssl_conf_groups(&s->conf, groups);
 mbedtls_ssl_conf_min_tls_version(&s->conf, MBEDTLS_SSL_VERSION_TLS1_2);
 mbedtls_ssl_conf_max_tls_version(&s->conf, MBEDTLS_SSL_VERSION_TLS1_2);
 mbedtls_ssl_conf_handshake_timeout(&s->conf, 100, 1000);
 mbedtls_ssl_conf_dtls_anti_replay(&s->conf, MBEDTLS_SSL_ANTI_REPLAY_ENABLED);
 TRY(mbedtls_ssl_conf_psk(&s->conf, key, 32, s->identity, sizeof(s->identity)));
 if (server) {
  TRY(mbedtls_ssl_cookie_setup(&s->cookie));
  mbedtls_ssl_conf_dtls_cookies(&s->conf, mbedtls_ssl_cookie_write,
                               mbedtls_ssl_cookie_check, &s->cookie);
 }
 TRY(mbedtls_ssl_setup(&s->ssl, &s->conf));
 mbedtls_ssl_set_bio(&s->ssl, io, send, receive, NULL);
 mbedtls_ssl_set_timer_cb(&s->ssl, s, set_timer, get_timer);
 mbedtls_ssl_set_mtu(&s->ssl, RF_DTLS_MTU);
 if (server) TRY(mbedtls_ssl_set_client_transport_id(&s->ssl, s->identity, sizeof(s->identity)));
 return 0;
fail:
 rf_dtls_free(s); return rc;
}
static int handshake(struct rf_dtls *s)
{
 int rc = mbedtls_ssl_handshake(&s->ssl);
 if (s->server && rc == MBEDTLS_ERR_SSL_HELLO_VERIFY_REQUIRED) {
  rc = mbedtls_ssl_session_reset(&s->ssl); if (rc) return rc;
  mbedtls_ssl_set_mtu(&s->ssl, RF_DTLS_MTU);
  rc = mbedtls_ssl_set_client_transport_id(&s->ssl, s->identity, sizeof(s->identity));
  return rc ? rc : MBEDTLS_ERR_SSL_WANT_READ;
 }
 if (!rc && mbedtls_ssl_get_ciphersuite_id_from_ssl(&s->ssl) != suites[0]) return MBEDTLS_ERR_SSL_BAD_INPUT_DATA;
 return rc;
}
int rf_dtls_init(struct rf_dtls *s, bool server, const uint8_t id[16], const uint8_t key[32],
                 void *io, mbedtls_ssl_send_t *send, mbedtls_ssl_recv_t *receive)
{
 k_mutex_lock(&radio_crypto_mutex, K_FOREVER);
 int rc = initialize(s, server, id, key, io, send, receive);
 k_mutex_unlock(&radio_crypto_mutex); return rc;
}
int rf_dtls_handshake(struct rf_dtls *s)
{
 k_mutex_lock(&radio_crypto_mutex, K_FOREVER);
 int rc = handshake(s); k_mutex_unlock(&radio_crypto_mutex); return rc;
}
int rf_dtls_read(struct rf_dtls *s, uint8_t *data, size_t length)
{
 k_mutex_lock(&radio_crypto_mutex, K_FOREVER);
 int rc = mbedtls_ssl_read(&s->ssl, data, length);
 k_mutex_unlock(&radio_crypto_mutex); return rc;
}
int rf_dtls_write(struct rf_dtls *s, const uint8_t *data, size_t length)
{
 k_mutex_lock(&radio_crypto_mutex, K_FOREVER);
 int rc = mbedtls_ssl_write(&s->ssl, data, length);
 k_mutex_unlock(&radio_crypto_mutex); return rc;
}
```

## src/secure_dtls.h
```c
/* SPDX-License-Identifier: MIT */
#ifndef MINEW_SECURE_DTLS_H
#define MINEW_SECURE_DTLS_H
#include <mbedtls/ssl.h>
#include <mbedtls/ssl_cookie.h>
#include <stdint.h>
#include <stdbool.h>
#include <zephyr/kernel.h>
extern struct k_mutex radio_crypto_mutex;

#define RF_DTLS_MTU 255
#define RF_PAIR_ID_BYTES 16
#define RF_PAIR_KEY_BYTES 32
struct rf_dtls {
 mbedtls_ssl_context ssl;
 mbedtls_ssl_config conf;
 mbedtls_ssl_cookie_ctx cookie;
 int64_t timer_start;
 uint32_t intermediate, final;
 uint8_t identity[RF_PAIR_ID_BYTES + 12];
 bool server, initialized;
};
int rf_dtls_init(struct rf_dtls *s, bool server, const uint8_t id[16], const uint8_t key[32],
                 void *io, mbedtls_ssl_send_t *send, mbedtls_ssl_recv_t *receive);
int rf_dtls_handshake(struct rf_dtls *s);
int rf_dtls_read(struct rf_dtls *s, uint8_t *data, size_t length);
int rf_dtls_write(struct rf_dtls *s, const uint8_t *data, size_t length);
void rf_dtls_free(struct rf_dtls *s);
#endif
```
